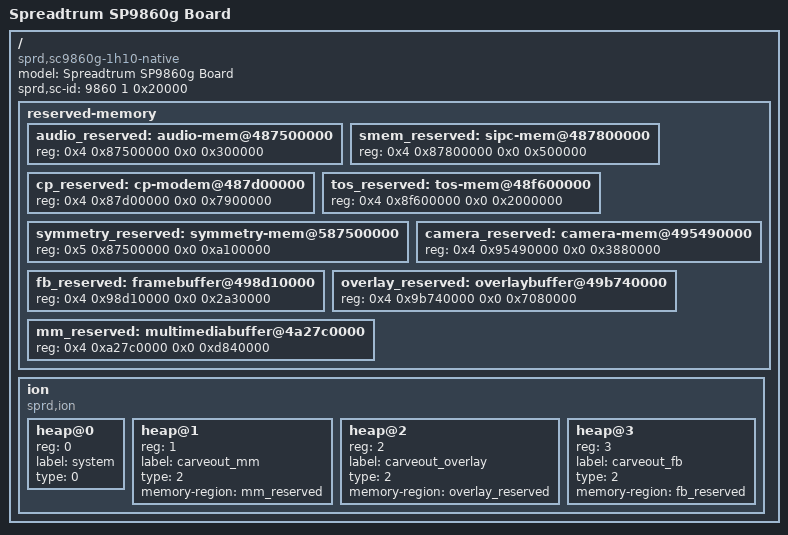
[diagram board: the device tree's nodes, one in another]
/*
 * Spreadtrum SP9860g board DTS file
 *
 * Copyright (C) 2016, Spreadtrum Communications Inc.
 *
 * This file is licensed under a dual GPLv2 or X11 license.
 */

/dts-v1/;

/ {
	model = "Spreadtrum SP9860g Board";

	compatible = "sprd,sc9860g-1h10-native";

	sprd,sc-id = <9860 1 0x20000>;

	reserved-memory {
		#address-cells = <2>;
		#size-cells = <2>;
		ranges;

		audio_reserved: audio-mem@487500000 {
			reg = <0x4 0x87500000 0x0 0x300000>;
		};

		smem_reserved: sipc-mem@487800000 {
			reg = <0x4 0x87800000 0x0 0x500000>;
		};

		cp_reserved: cp-modem@487d00000 {
			reg = <0x4 0x87d00000 0x0 0x7900000>;
		};

		tos_reserved: tos-mem@48f600000 {
			reg = <0x4 0x8f600000 0x0 0x2000000>;
		};

		symmetry_reserved: symmetry-mem@587500000 {
			reg = <0x5 0x87500000 0x0 0xa100000>;
		};

		camera_reserved: camera-mem@495490000{
			reg = <0x4 0x95490000 0x0 0x3880000>;
		};

		fb_reserved: framebuffer@498d10000{
			reg = <0x4 0x98d10000 0x0 0x2a30000>;
		};

		overlay_reserved: overlaybuffer@49b740000{
			reg = <0x4 0x9b740000 0x0 0x7080000>;
		};

		mm_reserved: multimediabuffer@4a27c0000{
			reg = <0x4 0xa27c0000 0x0 0xd840000>;
		};
	};

	ion {
		compatible = "sprd,ion";
		#address-cells = <1>;
		#size-cells = <0>;

		heap@0 {
			reg = <0>;
			label = "system";
			type = <0>;
		};

		heap@1 {
			reg = <1>;
			label = "carveout_mm";
			type = <2>;
			memory-region = <&mm_reserved>;
		};

		heap@2 {
			reg = <2>;
			label = "carveout_overlay";
			type = <2>;
			memory-region = <&overlay_reserved>;
		};

		heap@3 {
			reg = <3>;
			label = "carveout_fb";
			type = <2>;
			memory-region = <&fb_reserved>;
		};
	};
};
